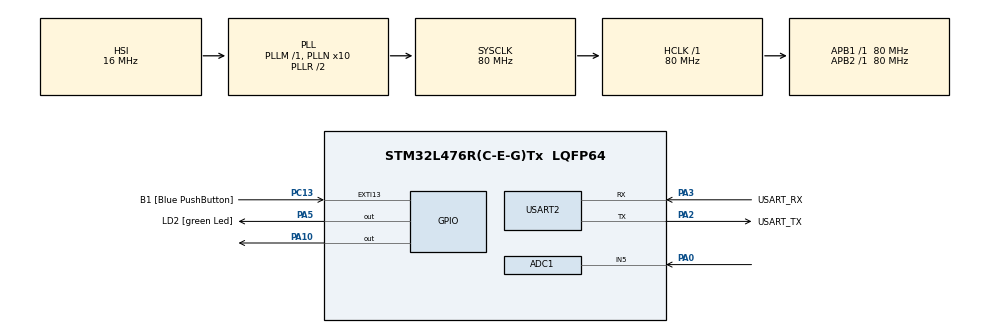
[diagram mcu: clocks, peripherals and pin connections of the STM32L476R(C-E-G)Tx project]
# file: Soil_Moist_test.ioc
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Mcu.Family=STM32L4
PA2.GPIO_PuPd=GPIO_NOPULL
RCC.CortexFreq_Value=80000000
PH0-OSC_IN\ (PH0).Signal=RCC_OSC_IN
PA3.GPIO_PuPd=GPIO_NOPULL
PA2.GPIO_Speed=GPIO_SPEED_FREQ_VERY_HIGH
PC15-OSC32_OUT\ (PC15).Mode=LSE-External-Oscillator
PC13.GPIO_Label=B1 [Blue PushButton]
PA3.GPIO_Speed=GPIO_SPEED_FREQ_VERY_HIGH
RCC.SYSCLKSource=RCC_SYSCLKSOURCE_PLLCLK
ProjectManager.StackSize=0x400
PB3\ (JTDO-TRACESWO).Signal=SYS_JTDO-SWO
PC14-OSC32_IN\ (PC14).Mode=LSE-External-Oscillator
PA14\ (JTCK-SWCLK).Signal=SYS_JTCK-SWCLK
RCC.HCLKFreq_Value=80000000
RCC.APB2TimFreq_Value=80000000
RCC.AHBFreq_Value=80000000
RCC.PREFETCH_ENABLE=1
ADC1.Channel-0\#ChannelRegularConversion=ADC_CHANNEL_5
RCC.HSE_VALUE=8000000
USART2.VirtualMode-Asynchronous=VM_ASYNC
PA5.GPIO_PuPd=GPIO_NOPULL
PC13.GPIO_PuPd=GPIO_NOPULL
ADC1.SamplingTime-0\#ChannelRegularConversion=ADC_SAMPLETIME_2CYCLES_5
PA0.Signal=ADCx_IN5
Mcu.Package=LQFP64
PA2.GPIO_Label=USART_TX
PA10.Signal=GPIO_Output
RCC.APB1TimFreq_Value=80000000
PA13\ (JTMS-SWDIO).Signal=SYS_JTMS-SWDIO
PA3.Signal=USART2_RX
PA2.GPIO_Mode=GPIO_MODE_AF_PP
RCC.MSI_VALUE=4000000
RCC.PLLSourceVirtual=RCC_PLLSOURCE_HSI
PA14\ (JTCK-SWCLK).Mode=Serial_Wire
ADC1.Rank-0\#ChannelRegularConversion=1
ADC1.OffsetNumber-0\#ChannelRegularConversion=ADC_OFFSET_NONE
PC13.Signal=GPXTI13
PC15-OSC32_OUT\ (PC15).Signal=RCC_OSC32_OUT
PA14\ (JTCK-SWCLK).GPIO_Label=TCK
PB3\ (JTDO-TRACESWO).GPIO_Label=SWO
PH1-OSC_OUT\ (PH1).Signal=RCC_OSC_OUT
PA3.Mode=Asynchronous
ProjectManager.TargetToolchain=STM32CubeIDE
PA3.GPIO_Mode=GPIO_MODE_AF_PP
RCC.USBFreq_Value=64000000
PA5.Signal=GPIO_Output
board=NUCLEO-L476RG
RCC.VCOOutputFreq_Value=160000000
RCC.APB2Freq_Value=80000000
PA5.GPIO_ModeDefaultOutputPP=GPIO_MODE_OUTPUT_PP
PA13\ (JTMS-SWDIO).GPIO_Label=TMS
RCC.ADCFreq_Value=64000000
Mcu.Name=STM32L476R(C-E-G)Tx
PA2.Signal=USART2_TX
PA13\ (JTMS-SWDIO).Mode=Serial_Wire
RCC.SYSCLKFreq_VALUE=80000000
ADC1.master=1
PA5.GPIO_Label=LD2 [green Led]
PC13.GPIO_ModeDefaultEXTI=GPIO_MODE_IT_FALLING
PC14-OSC32_IN\ (PC14).Signal=RCC_OSC32_IN
ProjectManager.HeapSize=0x200
RCC.HSI_VALUE=16000000
SH.ADCx_IN5.0=ADC1_IN5,IN5-Single-Ended
PA5.GPIO_Speed=GPIO_SPEED_FREQ_LOW
NVIC.PriorityGroup=NVIC_PRIORITYGROUP_4
ADC1.NbrOfConversionFlag=1
RCC.PLLN=10
PA2.Mode=Asynchronous
RCC.APB1Freq_Value=80000000
PA3.GPIO_Label=USART_RX

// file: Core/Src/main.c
/* USER CODE BEGIN Header */
/**
  ******************************************************************************
  * @file           : main.c
  * @brief          : Main program body
  ******************************************************************************
  * @attention
  *
  * <h2><center>&copy; Copyright (c) 2021 STMicroelectronics.
  * All rights reserved.</center></h2>
  *
  * This software component is licensed by ST under BSD 3-Clause license,
  * the "License"; You may not use this file except in compliance with the
  * License. You may obtain a copy of the License at:
  *                        opensource.org/licenses/BSD-3-Clause
  *
  ******************************************************************************
  */
/* USER CODE END Header */
#include "main.h"

/* USER CODE BEGIN Includes */
#include <string.h>
#include <stdio.h>

/* USER CODE END Includes */

ADC_HandleTypeDef hadc1;

UART_HandleTypeDef huart2;

void SystemClock_Config(void);
static void MX_GPIO_Init(void);
static void MX_USART2_UART_Init(void);
static void MX_ADC1_Init(void);

int main(void)
{
  /* USER CODE BEGIN 1 */
uint16_t raw;
uint16_t final;
char msg[50];
  /* USER CODE END 1 */

  /* MCU Configuration--------------------------------------------------------*/

  /* Reset of all peripherals, Initializes the Flash interface and the Systick. */
  HAL_Init();

  /* Configure the system clock */
  SystemClock_Config();

  /* Initialize all configured peripherals */
  MX_GPIO_Init();
  MX_USART2_UART_Init();
  MX_ADC1_Init();

  /* Infinite loop */
  /* USER CODE BEGIN WHILE */
  while (1)
  {
	  // set GPIO High
	  HAL_GPIO_WritePin(GPIOA, GPIO_PIN_10, GPIO_PIN_SET);
	  // Get ADC Value
	  HAL_ADC_Start(&hadc1);
	  HAL_ADC_PollForConversion(&hadc1, HAL_MAX_DELAY);
	  raw = HAL_ADC_GetValue(&hadc1);
	  //set GPIO low
	  HAL_GPIO_WritePin(GPIOA, GPIO_PIN_10, GPIO_PIN_SET);
	  // Convert to String then print
	  final = map_soil(raw, soinMin, soinMax, sooutMin, sooutMax);
	  sprintf(msg, "Wilgotnosc %d %% \r\n", final);
	  HAL_UART_Transmit(&huart2, (uint8_t*)msg, strlen(msg), HAL_MAX_DELAY);
	  // Wait 1s for another reading
	  HAL_Delay(1000);
    /* USER CODE END WHILE */

  }
}

void SystemClock_Config(void)
{
  RCC_OscInitTypeDef RCC_OscInitStruct = {0};
  RCC_ClkInitTypeDef RCC_ClkInitStruct = {0};
  RCC_PeriphCLKInitTypeDef PeriphClkInit = {0};

  /** Initializes the RCC Oscillators according to the specified parameters
  * in the RCC_OscInitTypeDef structure.
  */
  RCC_OscInitStruct.OscillatorType = RCC_OSCILLATORTYPE_HSI;
  RCC_OscInitStruct.HSIState = RCC_HSI_ON;
  RCC_OscInitStruct.HSICalibrationValue = RCC_HSICALIBRATION_DEFAULT;
  RCC_OscInitStruct.PLL.PLLState = RCC_PLL_ON;
  RCC_OscInitStruct.PLL.PLLSource = RCC_PLLSOURCE_HSI;
  RCC_OscInitStruct.PLL.PLLM = 1;
  RCC_OscInitStruct.PLL.PLLN = 10;
  RCC_OscInitStruct.PLL.PLLP = RCC_PLLP_DIV7;
  RCC_OscInitStruct.PLL.PLLQ = RCC_PLLQ_DIV2;
  RCC_OscInitStruct.PLL.PLLR = RCC_PLLR_DIV2;
  if (HAL_RCC_OscConfig(&RCC_OscInitStruct) != HAL_OK)
  {
    Error_Handler();
  }
  /** Initializes the CPU, AHB and APB buses clocks
  */
  RCC_ClkInitStruct.ClockType = RCC_CLOCKTYPE_HCLK|RCC_CLOCKTYPE_SYSCLK
                              |RCC_CLOCKTYPE_PCLK1|RCC_CLOCKTYPE_PCLK2;
  RCC_ClkInitStruct.SYSCLKSource = RCC_SYSCLKSOURCE_PLLCLK;
  RCC_ClkInitStruct.AHBCLKDivider = RCC_SYSCLK_DIV1;
  RCC_ClkInitStruct.APB1CLKDivider = RCC_HCLK_DIV1;
  RCC_ClkInitStruct.APB2CLKDivider = RCC_HCLK_DIV1;

  if (HAL_RCC_ClockConfig(&RCC_ClkInitStruct, FLASH_LATENCY_4) != HAL_OK)
  {
    Error_Handler();
  }
  PeriphClkInit.PeriphClockSelection = RCC_PERIPHCLK_USART2|RCC_PERIPHCLK_ADC;
  PeriphClkInit.Usart2ClockSelection = RCC_USART2CLKSOURCE_PCLK1;
  PeriphClkInit.AdcClockSelection = RCC_ADCCLKSOURCE_PLLSAI1;
  PeriphClkInit.PLLSAI1.PLLSAI1Source = RCC_PLLSOURCE_HSI;
  PeriphClkInit.PLLSAI1.PLLSAI1M = 1;
  PeriphClkInit.PLLSAI1.PLLSAI1N = 8;
  PeriphClkInit.PLLSAI1.PLLSAI1P = RCC_PLLP_DIV7;
  PeriphClkInit.PLLSAI1.PLLSAI1Q = RCC_PLLQ_DIV2;
  PeriphClkInit.PLLSAI1.PLLSAI1R = RCC_PLLR_DIV2;
  PeriphClkInit.PLLSAI1.PLLSAI1ClockOut = RCC_PLLSAI1_ADC1CLK;
  if (HAL_RCCEx_PeriphCLKConfig(&PeriphClkInit) != HAL_OK)
  {
    Error_Handler();
  }
  /** Configure the main internal regulator output voltage
  */
  if (HAL_PWREx_ControlVoltageScaling(PWR_REGULATOR_VOLTAGE_SCALE1) != HAL_OK)
  {
    Error_Handler();
  }
}

static void MX_ADC1_Init(void)
{

  ADC_MultiModeTypeDef multimode = {0};
  ADC_ChannelConfTypeDef sConfig = {0};

  /** Common config
  */
  hadc1.Instance = ADC1;
  hadc1.Init.ClockPrescaler = ADC_CLOCK_ASYNC_DIV1;
  hadc1.Init.Resolution = ADC_RESOLUTION_12B;
  hadc1.Init.DataAlign = ADC_DATAALIGN_RIGHT;
  hadc1.Init.ScanConvMode = ADC_SCAN_DISABLE;
  hadc1.Init.EOCSelection = ADC_EOC_SINGLE_CONV;
  hadc1.Init.LowPowerAutoWait = DISABLE;
  hadc1.Init.ContinuousConvMode = DISABLE;
  hadc1.Init.NbrOfConversion = 1;
  hadc1.Init.DiscontinuousConvMode = DISABLE;
  hadc1.Init.ExternalTrigConv = ADC_SOFTWARE_START;
  hadc1.Init.ExternalTrigConvEdge = ADC_EXTERNALTRIGCONVEDGE_NONE;
  hadc1.Init.DMAContinuousRequests = DISABLE;
  hadc1.Init.Overrun = ADC_OVR_DATA_PRESERVED;
  hadc1.Init.OversamplingMode = DISABLE;
  if (HAL_ADC_Init(&hadc1) != HAL_OK)
  {
    Error_Handler();
  }
  /** Configure the ADC multi-mode
  */
  multimode.Mode = ADC_MODE_INDEPENDENT;
  if (HAL_ADCEx_MultiModeConfigChannel(&hadc1, &multimode) != HAL_OK)
  {
    Error_Handler();
  }
  /** Configure Regular Channel
  */
  sConfig.Channel = ADC_CHANNEL_5;
  sConfig.Rank = ADC_REGULAR_RANK_1;
  sConfig.SamplingTime = ADC_SAMPLETIME_2CYCLES_5;
  sConfig.SingleDiff = ADC_SINGLE_ENDED;
  sConfig.OffsetNumber = ADC_OFFSET_NONE;
  sConfig.Offset = 0;
  if (HAL_ADC_ConfigChannel(&hadc1, &sConfig) != HAL_OK)
  {
    Error_Handler();
  }

}

static void MX_USART2_UART_Init(void)
{

  huart2.Instance = USART2;
  huart2.Init.BaudRate = 115200;
  huart2.Init.WordLength = UART_WORDLENGTH_8B;
  huart2.Init.StopBits = UART_STOPBITS_1;
  huart2.Init.Parity = UART_PARITY_NONE;
  huart2.Init.Mode = UART_MODE_TX_RX;
  huart2.Init.HwFlowCtl = UART_HWCONTROL_NONE;
  huart2.Init.OverSampling = UART_OVERSAMPLING_16;
  huart2.Init.OneBitSampling = UART_ONE_BIT_SAMPLE_DISABLE;
  huart2.AdvancedInit.AdvFeatureInit = UART_ADVFEATURE_NO_INIT;
  if (HAL_UART_Init(&huart2) != HAL_OK)
  {
    Error_Handler();
  }

}

static void MX_GPIO_Init(void)
{
  GPIO_InitTypeDef GPIO_InitStruct = {0};

  /* GPIO Ports Clock Enable */
  __HAL_RCC_GPIOC_CLK_ENABLE();
  __HAL_RCC_GPIOH_CLK_ENABLE();
  __HAL_RCC_GPIOA_CLK_ENABLE();
  __HAL_RCC_GPIOB_CLK_ENABLE();

  /*Configure GPIO pin Output Level */
  HAL_GPIO_WritePin(GPIOA, LD2_Pin|GPIO_PIN_10, GPIO_PIN_RESET);

  /*Configure GPIO pin : B1_Pin */
  GPIO_InitStruct.Pin = B1_Pin;
  GPIO_InitStruct.Mode = GPIO_MODE_IT_FALLING;
  GPIO_InitStruct.Pull = GPIO_NOPULL;
  HAL_GPIO_Init(B1_GPIO_Port, &GPIO_InitStruct);

  /*Configure GPIO pins : LD2_Pin PA10 */
  GPIO_InitStruct.Pin = LD2_Pin|GPIO_PIN_10;
  GPIO_InitStruct.Mode = GPIO_MODE_OUTPUT_PP;
  GPIO_InitStruct.Pull = GPIO_NOPULL;
  GPIO_InitStruct.Speed = GPIO_SPEED_FREQ_LOW;
  HAL_GPIO_Init(GPIOA, &GPIO_InitStruct);

}

void Error_Handler(void)
{
  __disable_irq();
  while (1)
  {
  }
}

/************************ (C) COPYRIGHT STMicroelectronics *****END OF FILE****/
